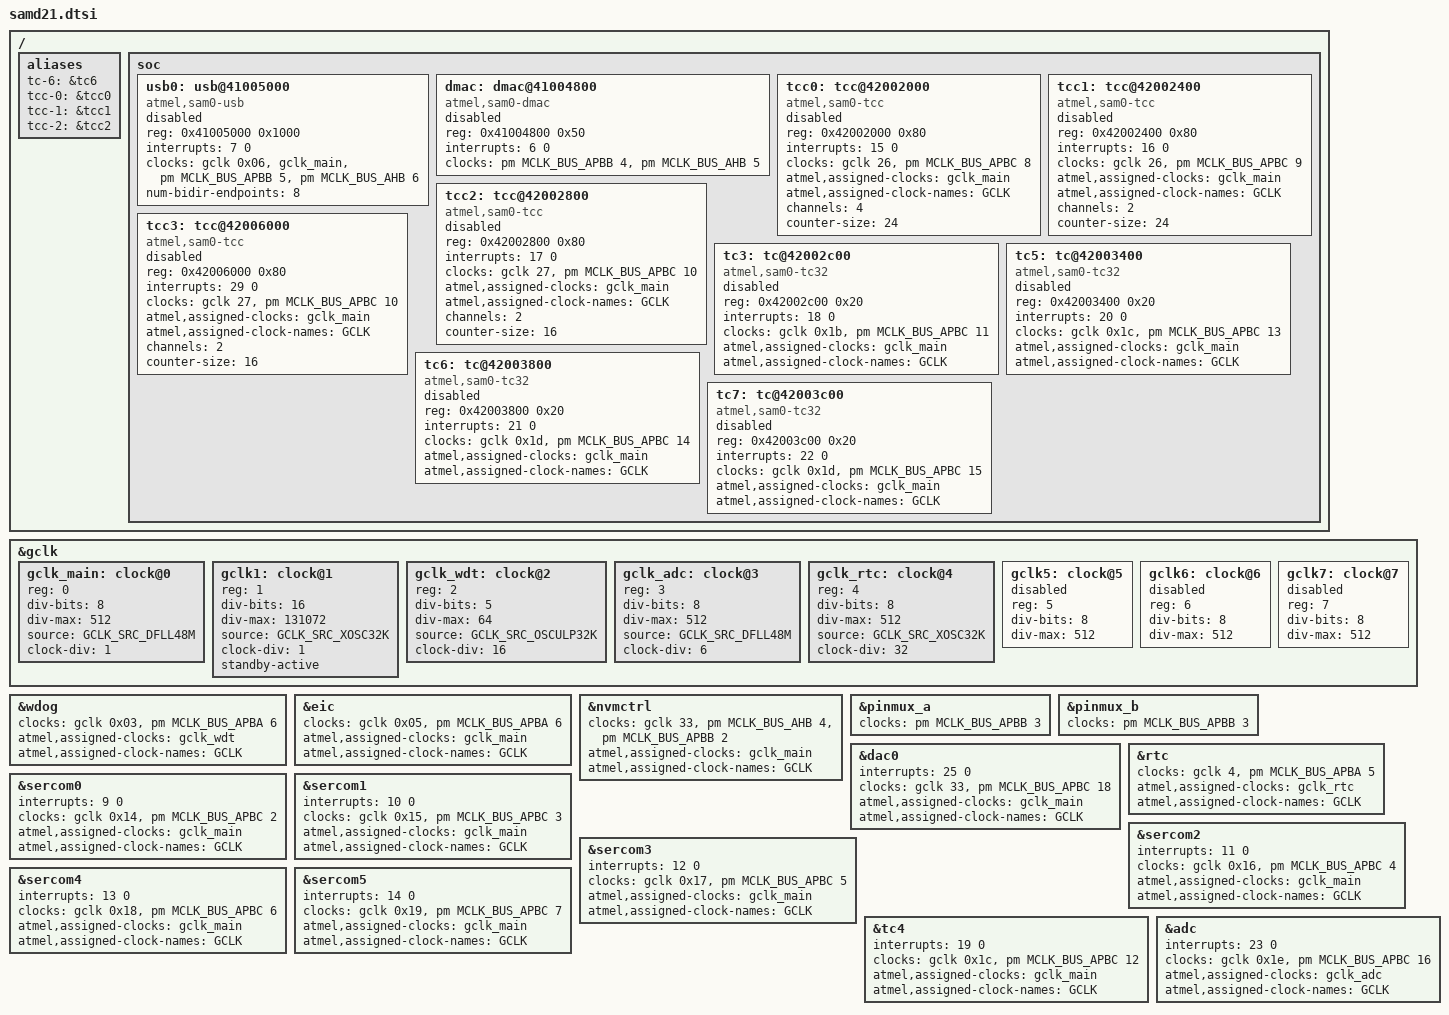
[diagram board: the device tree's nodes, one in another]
/*
 * Copyright (c) 2017 Google LLC.
 * Copyright (c) 2024 Gerson Fernando Budke <nandojve@gmail.com>
 *
 * SPDX-License-Identifier: Apache-2.0
 */

#include <atmel/samd2x.dtsi>

/ {
	aliases {
		tc-6 = &tc6;

		tcc-0 = &tcc0;
		tcc-1 = &tcc1;
		tcc-2 = &tcc2;
	};

	soc {
		usb0: usb@41005000 {
			compatible = "atmel,sam0-usb";
			reg = <0x41005000 0x1000>;
			interrupts = <7 0>;
			clocks = <&gclk 0x06>, <&gclk_main>, <&pm MCLK_BUS_APBB 5>, <&pm MCLK_BUS_AHB 6>;
			/*clock-names = "GCLK", "PM", "DMA";*/
			clock-names = "GCLK", "periph", "PM", "master";
			status = "disabled";

			num-bidir-endpoints = <8>;
		};

		dmac: dmac@41004800 {
			compatible = "atmel,sam0-dmac";
			reg = <0x41004800 0x50>;
			interrupts = <6 0>;
			clocks = <&pm MCLK_BUS_APBB 4>, <&pm MCLK_BUS_AHB 5>;
			clock-names = "PM", "master";
			status = "disabled";

			#dma-cells = <2>;
		};

		tcc0: tcc@42002000 {
			compatible = "atmel,sam0-tcc";
			reg = <0x42002000 0x80>;
			interrupts = <15 0>;
			clocks = <&gclk 26>, <&pm MCLK_BUS_APBC 8>;
			clock-names = "GCLK", "PM";
			atmel,assigned-clocks = <&gclk_main>;
			atmel,assigned-clock-names = "GCLK";
			status = "disabled";

			channels = <4>;
			counter-size = <24>;
		};

		tcc1: tcc@42002400 {
			compatible = "atmel,sam0-tcc";
			reg = <0x42002400 0x80>;
			interrupts = <16 0>;
			clocks = <&gclk 26>, <&pm MCLK_BUS_APBC 9>;
			clock-names = "GCLK", "PM";
			atmel,assigned-clocks = <&gclk_main>;
			atmel,assigned-clock-names = "GCLK";
			status = "disabled";

			channels = <2>;
			counter-size = <24>;
		};

		tcc2: tcc@42002800 {
			compatible = "atmel,sam0-tcc";
			reg = <0x42002800 0x80>;
			interrupts = <17 0>;
			clocks = <&gclk 27>, <&pm MCLK_BUS_APBC 10>;
			clock-names = "GCLK", "PM";
			atmel,assigned-clocks = <&gclk_main>;
			atmel,assigned-clock-names = "GCLK";
			status = "disabled";

			channels = <2>;
			counter-size = <16>;
		};

		tcc3: tcc@42006000 {
			/* Only supported in SAMD21x17D */
			compatible = "atmel,sam0-tcc";
			reg = <0x42006000 0x80>;
			interrupts = <29 0>;
			clocks = <&gclk 27>, <&pm MCLK_BUS_APBC 10>;
			clock-names = "GCLK", "PM";
			atmel,assigned-clocks = <&gclk_main>;
			atmel,assigned-clock-names = "GCLK";
			status = "disabled";

			channels = <2>;
			counter-size = <16>;
		};

		tc3: tc@42002c00 {
			compatible = "atmel,sam0-tc32";
			reg = <0x42002c00 0x20>;
			interrupts = <18 0>;
			clocks = <&gclk 0x1b>, <&pm MCLK_BUS_APBC 11>;
			clock-names = "GCLK", "PM";
			atmel,assigned-clocks = <&gclk_main>;
			atmel,assigned-clock-names = "GCLK";
			status = "disabled";
		};

		tc5: tc@42003400 {
			compatible = "atmel,sam0-tc32";
			reg = <0x42003400 0x20>;
			interrupts = <20 0>;
			clocks = <&gclk 0x1c>, <&pm MCLK_BUS_APBC 13>;
			clock-names = "GCLK", "PM";
			atmel,assigned-clocks = <&gclk_main>;
			atmel,assigned-clock-names = "GCLK";
			status = "disabled";
		};

		tc6: tc@42003800 {
			compatible = "atmel,sam0-tc32";
			reg = <0x42003800 0x20>;
			interrupts = <21 0>;
			clocks = <&gclk 0x1d>, <&pm MCLK_BUS_APBC 14>;
			clock-names = "GCLK", "PM";
			atmel,assigned-clocks = <&gclk_main>;
			atmel,assigned-clock-names = "GCLK";
			status = "disabled";
		};

		tc7: tc@42003c00 {
			compatible = "atmel,sam0-tc32";
			reg = <0x42003c00 0x20>;
			interrupts = <22 0>;
			clocks = <&gclk 0x1d>, <&pm MCLK_BUS_APBC 15>;
			clock-names = "GCLK", "PM";
			atmel,assigned-clocks = <&gclk_main>;
			atmel,assigned-clock-names = "GCLK";
			status = "disabled";
		};
	};
};

&gclk {
	#address-cells = <1>;
	#size-cells = <0>;

	gclk_main: clock@0 {
		reg = <0>;
		#clock-cells = <0>;
		#atmel,assigned-clock-cells = <0>;
		div-bits = <8>;
		div-max = <512>;

		source = <GCLK_SRC_DFLL48M>;
		clock-div = <1>;
	};

	gclk1: clock@1 {
		reg = <1>;
		#clock-cells = <0>;
		#atmel,assigned-clock-cells = <0>;
		div-bits = <16>;
		div-max = <131072>;

		source = <GCLK_SRC_XOSC32K>;
		clock-div = <1>;
		standby-active;
	};

	gclk_wdt: clock@2 {
		reg = <2>;
		#clock-cells = <0>;
		#atmel,assigned-clock-cells = <0>;
		div-bits = <5>;
		div-max = <64>;

		source = <GCLK_SRC_OSCULP32K>;
		clock-div = <16>;
	};

	gclk_adc: clock@3 {
		reg = <3>;
		#clock-cells = <0>;
		#atmel,assigned-clock-cells = <0>;
		div-bits = <8>;
		div-max = <512>;

		source = <GCLK_SRC_DFLL48M>;
		clock-div = <6>;
	};

	gclk_rtc: clock@4 {
		reg = <4>;
		#clock-cells = <0>;
		#atmel,assigned-clock-cells = <0>;
		div-bits = <8>;
		div-max = <512>;

		source = <GCLK_SRC_XOSC32K>;
		/* This clock is used by the RTC. In calendar mode, the prescalar
		 * should be set to 32 to generate the required 1024 Hz clock.
		 */
		clock-div = <32>;
	};

	gclk5: clock@5 {
		reg = <5>;
		#clock-cells = <0>;
		#atmel,assigned-clock-cells = <0>;
		div-bits = <8>;
		div-max = <512>;

		status = "disabled";
	};

	gclk6: clock@6 {
		reg = <6>;
		#clock-cells = <0>;
		#atmel,assigned-clock-cells = <0>;
		div-bits = <8>;
		div-max = <512>;

		status = "disabled";
	};

	gclk7: clock@7 {
		reg = <7>;
		#clock-cells = <0>;
		#atmel,assigned-clock-cells = <0>;
		div-bits = <8>;
		div-max = <512>;

		status = "disabled";
	};
};


&wdog {
	clocks = <&gclk 0x03>, <&pm MCLK_BUS_APBA 6>;
	clock-names = "GCLK", "PM";
	atmel,assigned-clocks = <&gclk_wdt>;
	atmel,assigned-clock-names = "GCLK";
};

&eic {
	clocks = <&gclk 0x05>, <&pm MCLK_BUS_APBA 6>;
	clock-names = "GCLK", "PM";
	atmel,assigned-clocks = <&gclk_main>;
	atmel,assigned-clock-names = "GCLK";
};

&nvmctrl {
	clocks = <&gclk 33>, <&pm MCLK_BUS_AHB 4>, <&pm MCLK_BUS_APBB 2>;
	clock-names = "GCLK", "master", "PM";
	atmel,assigned-clocks = <&gclk_main>;
	atmel,assigned-clock-names = "GCLK";
};

&pinmux_a {
	clocks = <&pm MCLK_BUS_APBB 3>;
	clock-names = "PM";
};

&pinmux_b {
	clocks = <&pm MCLK_BUS_APBB 3>;
	clock-names = "PM";
};

&dac0 {
	interrupts = <25 0>;
	clocks = <&gclk 33>, <&pm MCLK_BUS_APBC 18>;
	clock-names = "GCLK", "PM";
	atmel,assigned-clocks = <&gclk_main>;
	atmel,assigned-clock-names = "GCLK";
};

&rtc {
	clocks = <&gclk 4>, <&pm MCLK_BUS_APBA 5>;
	clock-names = "GCLK", "PM";
	atmel,assigned-clocks = <&gclk_rtc>;
	atmel,assigned-clock-names = "GCLK";
};

&sercom0 {
	interrupts = <9 0>;
	clocks = <&gclk 0x14>, <&pm MCLK_BUS_APBC 2>;
	clock-names = "GCLK", "PM";
	atmel,assigned-clocks = <&gclk_main>;
	atmel,assigned-clock-names = "GCLK";
};

&sercom1 {
	interrupts = <10 0>;
	clocks = <&gclk 0x15>, <&pm MCLK_BUS_APBC 3>;
	clock-names = "GCLK", "PM";
	atmel,assigned-clocks = <&gclk_main>;
	atmel,assigned-clock-names = "GCLK";
};

&sercom2 {
	interrupts = <11 0>;
	clocks = <&gclk 0x16>, <&pm MCLK_BUS_APBC 4>;
	clock-names = "GCLK", "PM";
	atmel,assigned-clocks = <&gclk_main>;
	atmel,assigned-clock-names = "GCLK";
};

&sercom3 {
	interrupts = <12 0>;
	clocks = <&gclk 0x17>, <&pm MCLK_BUS_APBC 5>;
	clock-names = "GCLK", "PM";
	atmel,assigned-clocks = <&gclk_main>;
	atmel,assigned-clock-names = "GCLK";
};

&sercom4 {
	interrupts = <13 0>;
	clocks = <&gclk 0x18>, <&pm MCLK_BUS_APBC 6>;
	clock-names = "GCLK", "PM";
	atmel,assigned-clocks = <&gclk_main>;
	atmel,assigned-clock-names = "GCLK";
};

&sercom5 {
	interrupts = <14 0>;
	clocks = <&gclk 0x19>, <&pm MCLK_BUS_APBC 7>;
	clock-names = "GCLK", "PM";
	atmel,assigned-clocks = <&gclk_main>;
	atmel,assigned-clock-names = "GCLK";
};

&tc4 {
	interrupts = <19 0>;
	clocks = <&gclk 0x1c>, <&pm MCLK_BUS_APBC 12>;
	clock-names = "GCLK", "PM";
	atmel,assigned-clocks = <&gclk_main>;
	atmel,assigned-clock-names = "GCLK";
};

&adc {
	interrupts = <23 0>;
	interrupt-names = "resrdy";
	clocks = <&gclk 0x1e>, <&pm MCLK_BUS_APBC 16>;
	clock-names = "GCLK", "PM";
	/*
	 * 2.1 MHz is ADC max clock
	 * 8 MHz GCLK / 4 = 2 MHz
	 * Generator 3: DFLL48M / 8MHz
	 */
	atmel,assigned-clocks = <&gclk_adc>;
	atmel,assigned-clock-names = "GCLK";
};
